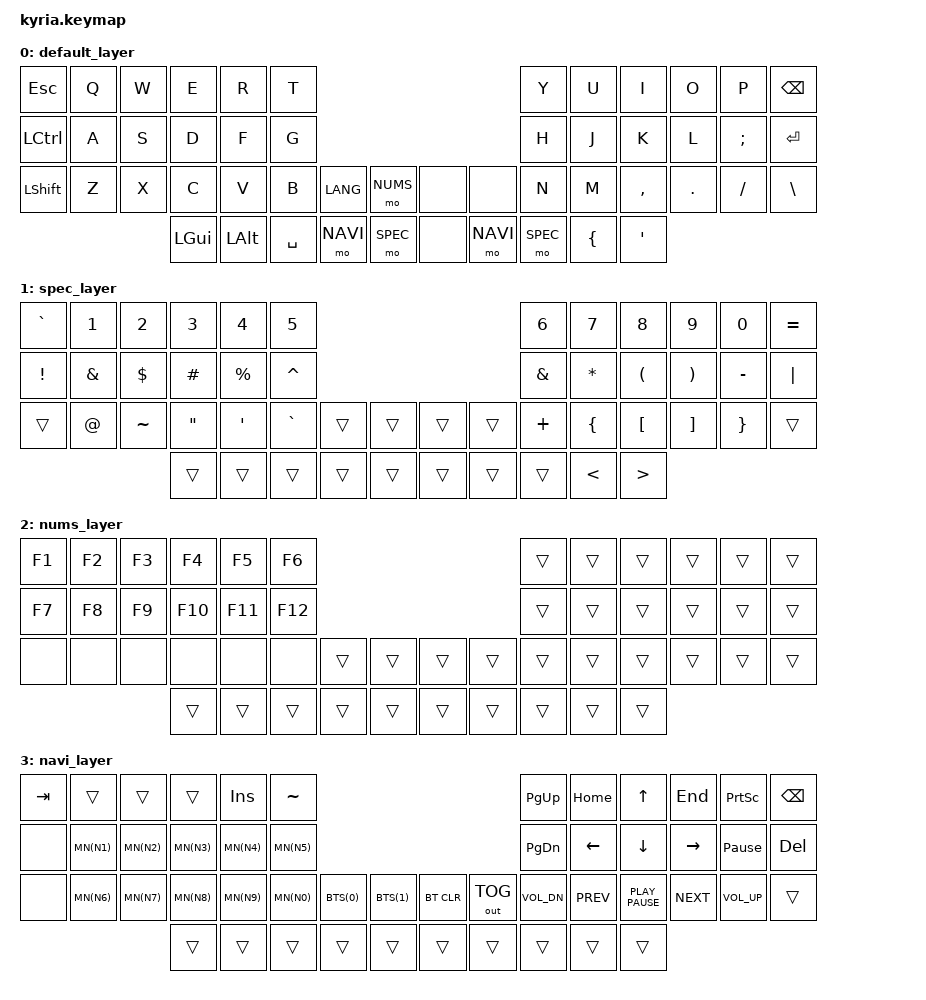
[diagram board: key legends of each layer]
/*
 * Copyright (c) 2020 The ZMK Contributors
 *
 * SPDX-License-Identifier: MIT
 */

#include <behaviors.dtsi>
#include <dt-bindings/zmk/keys.h>
#include <dt-bindings/zmk/bt.h>
#include <dt-bindings/zmk/outputs.h>
#include <dt-bindings/zmk/ext_power.h>

#define SPEC 1
#define NUMS 2
#define NAVI 3
#define LANG CLCK
#define BTS(n) &bt BT_SEL n
#define MN(n) &kp LG n

/ {
	keymap {
		compatible = "zmk,keymap";

		default_layer {
// -----------------------------------------------------------------------------------------------------------
// | ESC   |  Q  |  W  |  E    |   R   |  T   |                             |  Y  |  U   |  I  |  O  |  P  |  BSPC |
// | CTRL  |  A  |  S  |  D    |   F   |  G   |                             |  H  |  J   |  K  |  L  |  ;  | ENTER |
// | SHIFT |  Z  |  X  |  C    |   V   |  B   | LANG |     | |      |       |  N  |  M   |  ,  |  .  |  /  |   \   |
//                     | LGUI  |  LALT | SPACE| NAVI |NUMS | |      | NAVI  | SPEC|  х   |  э  |
			bindings = <
&kp ESC   &kp Q  &kp W  &kp E    &kp R    &kp T                                            &kp Y     &kp U    &kp I     &kp O   &kp P     &kp BSPC
&kp LCTRL &kp A  &kp S  &kp D    &kp F    &kp G                                            &kp H     &kp J    &kp K     &kp L   &kp SEMI  &kp ENTER
&kp LSHFT &kp Z  &kp X  &kp C    &kp V    &kp B     &kp LANG &mo NUMS  &none     &none     &kp N     &kp M    &kp COMMA &kp DOT &kp SLASH &kp BACKSLASH
                        &kp LGUI &kp LALT &kp SPACE &mo NAVI &mo SPEC  &none     &mo NAVI  &mo SPEC  &kp LBRC &kp SQT
			>;

			sensor-bindings = <&inc_dec_kp PG_UP PG_DN>;

		};

		spec_layer {
// ------------------------------------------------------------------------------------------------------
// |  `  |  1  |  2   |  3  |  4  |   5   |                      |   6   |   7   |  8  |  9  |  0  |  =  |
// |  !  |  &  |  $   |  #  |  %  |   ^   |                      |   &   |   *   |  (  |  )  |  -  |  |  |
// |     |  @  |  ~   |  "  |  '  |   `   |        |  |          |   +   |   {   |  [  |  ]  |  }  |     |
//                    |     |     |       |        |  |          |       |   <   |  >  |
			bindings = <
&kp GRAVE &kp N1   &kp N2      &kp N3     &kp N4    &kp N5                                  &kp N6    &kp N7    &kp N8    &kp N9    &kp N0     &kp EQUAL
&kp EXCL  &kp AMPS &kp DOLLAR  &kp HASH   &kp PRCNT &kp CARET                               &kp AMPS  &kp ASTRK &kp LPAR  &kp RPAR  &kp MINUS  &kp PIPE
&trans    &kp AT   &kp TILDE   &kp DQT    &kp SQT   &kp GRAVE &trans &trans   &trans &trans &kp PLUS  &kp LBRC  &kp LBKT  &kp RBKT  &kp RBRC   &trans
                               &trans     &trans    &trans    &trans &trans   &trans &trans &trans    &kp LT    &kp GT
			>;

			sensor-bindings = <&inc_dec_kp UP DOWN>;
		};

		nums_layer {
// ----------------------------------------------------------------------------------------------------
// | F1  | F2  | F3  | F4  | F5  |  F6   |                      |       |       |     |     |     |     |
// | F7  | F8  | F9  | F10 | F11 |  F12  |                      |       |       |     |     |     |     |
// |     |     |     |     |     |       |    |    |  |    |    |       |       |     |     |     |     |
//                   |     |     |       |    |    |  |    |    |       |       |     |
			bindings = <
&kp F1  &kp F2 &kp F3 &kp F4   &kp F5   &kp F6                                   &trans  &trans   &trans  &trans  &trans  &trans
&kp F7  &kp F8 &kp F9 &kp F10  &kp F11  &kp F12                                  &trans  &trans   &trans  &trans  &trans  &trans
&none   &none  &none  &none    &none    &none     &trans &trans   &trans &trans  &trans  &trans   &trans  &trans  &trans  &trans
                      &trans   &trans   &trans    &trans &trans   &trans &trans  &trans  &trans   &trans
			>;
		};

		navi_layer {
// ----------------------------------------------------------------------------------------------------
// | TAB  |     |     |      | INS |  ё  |                               | PG_UP  | HOME | UP   | END  | PSCR | BSPC |
// |META+1|     |     |      |     |     |                               | PG_DN  | LEFT | DOWN |RIGHT | PAUSE| DEL  |
// |      |     |     |META+0| F11 | F12 | BT1 | BT2 |  | BT CLR | OUT_T | VOLDN  | PREV |  PP  | NEXT |VOLUP |      |
//                    |      |     |     |     |     |  |        |       |        |      |
			bindings = <
&kp TAB &trans &trans &trans   &kp INS  &kp TILDE                                       &kp PG_UP     &kp HOME    &kp UP           &kp END    &kp PSCRN       &kp BSPC
&none   MN(N1) MN(N2) MN(N3)   MN(N4)   MN(N5)                                          &kp PG_DN     &kp LEFT    &kp DOWN         &kp RIGHT  &kp PAUSE_BREAK &kp DEL
&none   MN(N6) MN(N7) MN(N8)   MN(N9)   MN(N0)   BTS(0) BTS(1)  &bt BT_CLR &out OUT_TOG &kp C_VOL_DN  &kp K_PREV  &kp K_PLAY_PAUSE &kp K_NEXT &kp C_VOL_UP    &trans
                      &trans   &trans   &trans   &trans &trans  &trans     &trans       &trans        &trans      &trans
			>;

			sensor-bindings = <&inc_dec_kp C_VOL_UP C_VOL_DN>;
		};
	};
};
